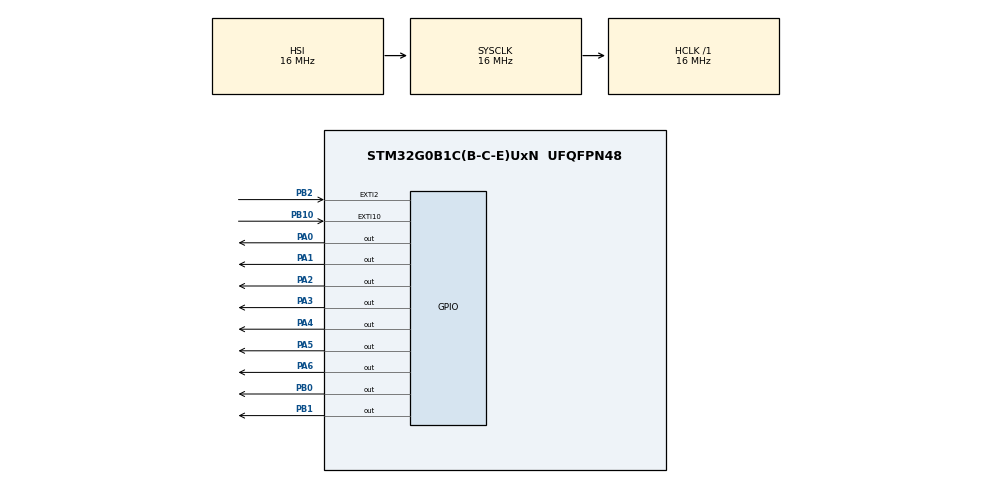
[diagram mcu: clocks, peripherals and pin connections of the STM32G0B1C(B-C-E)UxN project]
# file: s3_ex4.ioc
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Mcu.Family=STM32G0
Mcu.Name=STM32G0B1C(B-C-E)UxN
Mcu.Package=UFQFPN48
NVIC.EXTI2_3_IRQn=true\:0\:0\:false\:false\:true\:true\:true\:true
NVIC.EXTI4_15_IRQn=true\:0\:0\:false\:false\:true\:true\:true\:true
PA0.Signal=GPIO_Output
PA1.Signal=GPIO_Output
PA2.Signal=GPIO_Output
PA3.Signal=GPIO_Output
PA4.Signal=GPIO_Output
PA5.Signal=GPIO_Output
PA6.Signal=GPIO_Output
PB0.Signal=GPIO_Output
PB1.Signal=GPIO_Output
PB10.GPIO_ModeDefaultEXTI=GPIO_MODE_IT_FALLING
PB10.GPIO_PuPd=GPIO_PULLUP
PB10.Signal=GPXTI10
PB2.GPIO_ModeDefaultEXTI=GPIO_MODE_IT_FALLING
PB2.GPIO_PuPd=GPIO_PULLUP
PB2.Signal=GPXTI2
ProjectManager.HeapSize=0x200
ProjectManager.StackSize=0x400
ProjectManager.TargetToolchain=STM32CubeIDE
RCC.AHBFreq_Value=16000000
RCC.CortexFreq_Value=16000000
RCC.EXTERNAL_CLOCK_VALUE=48000
RCC.HCLKFreq_Value=16000000
RCC.HSE_VALUE=8000000
RCC.HSI48_VALUE=48000000
RCC.HSI_VALUE=16000000
RCC.LSE_VALUE=32768
RCC.SYSCLKFreq_VALUE=16000000
RCC.USBFreq_Value=48000000
RCC.VCOOutputFreq_Value=128000000
board=custom

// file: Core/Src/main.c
/* USER CODE BEGIN Header */
/**
  ******************************************************************************
  * @file           : main.c
  * @brief          : Main program body
  ******************************************************************************
  * @attention
  *
  * Copyright (c) 2023 STMicroelectronics.
  * All rights reserved.
  *
  * This software is licensed under terms that can be found in the LICENSE file
  * in the root directory of this software component.
  * If no LICENSE file comes with this software, it is provided AS-IS.
  *
  ******************************************************************************
  */
/* USER CODE END Header */
#include "main.h"
void SystemClock_Config(void);
static void MX_GPIO_Init(void);
int8_t i=0;
void HAL_GPIO_EXTI_Falling_Callback(uint16_t GPIO_Pin)
{
    if(GPIO_Pin ==GPIO_PIN_2)
    {
    	  i++;
    	  if(i==100)
    	   i=99;
    }
    else  if(GPIO_Pin ==GPIO_PIN_10)
       {
    	if(i>0)
    	  i--;
       }
 }

int main(void)
{
    HAL_Init();
   SystemClock_Config();
   MX_GPIO_Init();
  /* USER CODE BEGIN WHILE */
   unsigned char decode[10]={0x003f,0x0006,0x005B,0x004f,0x0066,0x006d,0x007d,0x0007, 0x007f,0x006f};
   unsigned char a,b;
  while (1)
  {
	  a=i%10;
	  HAL_GPIO_WritePin(GPIOB, GPIO_PIN_0, 1);
	  HAL_GPIO_WritePin(GPIOB, GPIO_PIN_1, 0);
	  GPIOA->ODR = decode[a]; //Displaying ones
	  HAL_Delay(5);
	  b=i/10;
	  HAL_GPIO_WritePin(GPIOB, GPIO_PIN_0, 0);
	  HAL_GPIO_WritePin(GPIOB, GPIO_PIN_1, 1);
	  GPIOA->ODR = decode[b]; //Displaying tens
	  HAL_Delay(5);
  }

  /* USER CODE END WHILE */
}

void SystemClock_Config(void)
{
  RCC_OscInitTypeDef RCC_OscInitStruct = {0};
  RCC_ClkInitTypeDef RCC_ClkInitStruct = {0};

  /** Configure the main internal regulator output voltage
  */
  HAL_PWREx_ControlVoltageScaling(PWR_REGULATOR_VOLTAGE_SCALE1);

  /** Initializes the RCC Oscillators according to the specified parameters
  * in the RCC_OscInitTypeDef structure.
  */
  RCC_OscInitStruct.OscillatorType = RCC_OSCILLATORTYPE_HSI;
  RCC_OscInitStruct.HSIState = RCC_HSI_ON;
  RCC_OscInitStruct.HSIDiv = RCC_HSI_DIV1;
  RCC_OscInitStruct.HSICalibrationValue = RCC_HSICALIBRATION_DEFAULT;
  RCC_OscInitStruct.PLL.PLLState = RCC_PLL_NONE;
  if (HAL_RCC_OscConfig(&RCC_OscInitStruct) != HAL_OK)
  {
    Error_Handler();
  }

  /** Initializes the CPU, AHB and APB buses clocks
  */
  RCC_ClkInitStruct.ClockType = RCC_CLOCKTYPE_HCLK|RCC_CLOCKTYPE_SYSCLK
                              |RCC_CLOCKTYPE_PCLK1;
  RCC_ClkInitStruct.SYSCLKSource = RCC_SYSCLKSOURCE_HSI;
  RCC_ClkInitStruct.AHBCLKDivider = RCC_SYSCLK_DIV1;
  RCC_ClkInitStruct.APB1CLKDivider = RCC_HCLK_DIV1;

  if (HAL_RCC_ClockConfig(&RCC_ClkInitStruct, FLASH_LATENCY_0) != HAL_OK)
  {
    Error_Handler();
  }
}

static void MX_GPIO_Init(void)
{
  GPIO_InitTypeDef GPIO_InitStruct = {0};

  /* GPIO Ports Clock Enable */
  __HAL_RCC_GPIOA_CLK_ENABLE();
  __HAL_RCC_GPIOB_CLK_ENABLE();

  /*Configure GPIO pin Output Level */
  HAL_GPIO_WritePin(GPIOA, GPIO_PIN_0|GPIO_PIN_1|GPIO_PIN_2|GPIO_PIN_3
                          |GPIO_PIN_4|GPIO_PIN_5|GPIO_PIN_6, GPIO_PIN_RESET);

  /*Configure GPIO pin Output Level */
  HAL_GPIO_WritePin(GPIOB, GPIO_PIN_0|GPIO_PIN_1, GPIO_PIN_RESET);

  /*Configure GPIO pins : PA0 PA1 PA2 PA3
                           PA4 PA5 PA6 */
  GPIO_InitStruct.Pin = GPIO_PIN_0|GPIO_PIN_1|GPIO_PIN_2|GPIO_PIN_3
                          |GPIO_PIN_4|GPIO_PIN_5|GPIO_PIN_6;
  GPIO_InitStruct.Mode = GPIO_MODE_OUTPUT_PP;
  GPIO_InitStruct.Pull = GPIO_NOPULL;
  GPIO_InitStruct.Speed = GPIO_SPEED_FREQ_LOW;
  HAL_GPIO_Init(GPIOA, &GPIO_InitStruct);

  /*Configure GPIO pins : PB0 PB1 */
  GPIO_InitStruct.Pin = GPIO_PIN_0|GPIO_PIN_1;
  GPIO_InitStruct.Mode = GPIO_MODE_OUTPUT_PP;
  GPIO_InitStruct.Pull = GPIO_NOPULL;
  GPIO_InitStruct.Speed = GPIO_SPEED_FREQ_LOW;
  HAL_GPIO_Init(GPIOB, &GPIO_InitStruct);

  /*Configure GPIO pins : PB2 PB10 */
  GPIO_InitStruct.Pin = GPIO_PIN_2|GPIO_PIN_10;
  GPIO_InitStruct.Mode = GPIO_MODE_IT_FALLING;
  GPIO_InitStruct.Pull = GPIO_PULLUP;
  HAL_GPIO_Init(GPIOB, &GPIO_InitStruct);

  /* EXTI interrupt init*/
  HAL_NVIC_SetPriority(EXTI2_3_IRQn, 0, 0);
  HAL_NVIC_EnableIRQ(EXTI2_3_IRQn);

  HAL_NVIC_SetPriority(EXTI4_15_IRQn, 0, 0);
  HAL_NVIC_EnableIRQ(EXTI4_15_IRQn);

}

void Error_Handler(void)
{
  __disable_irq();
  while (1)
  {
  }
}
